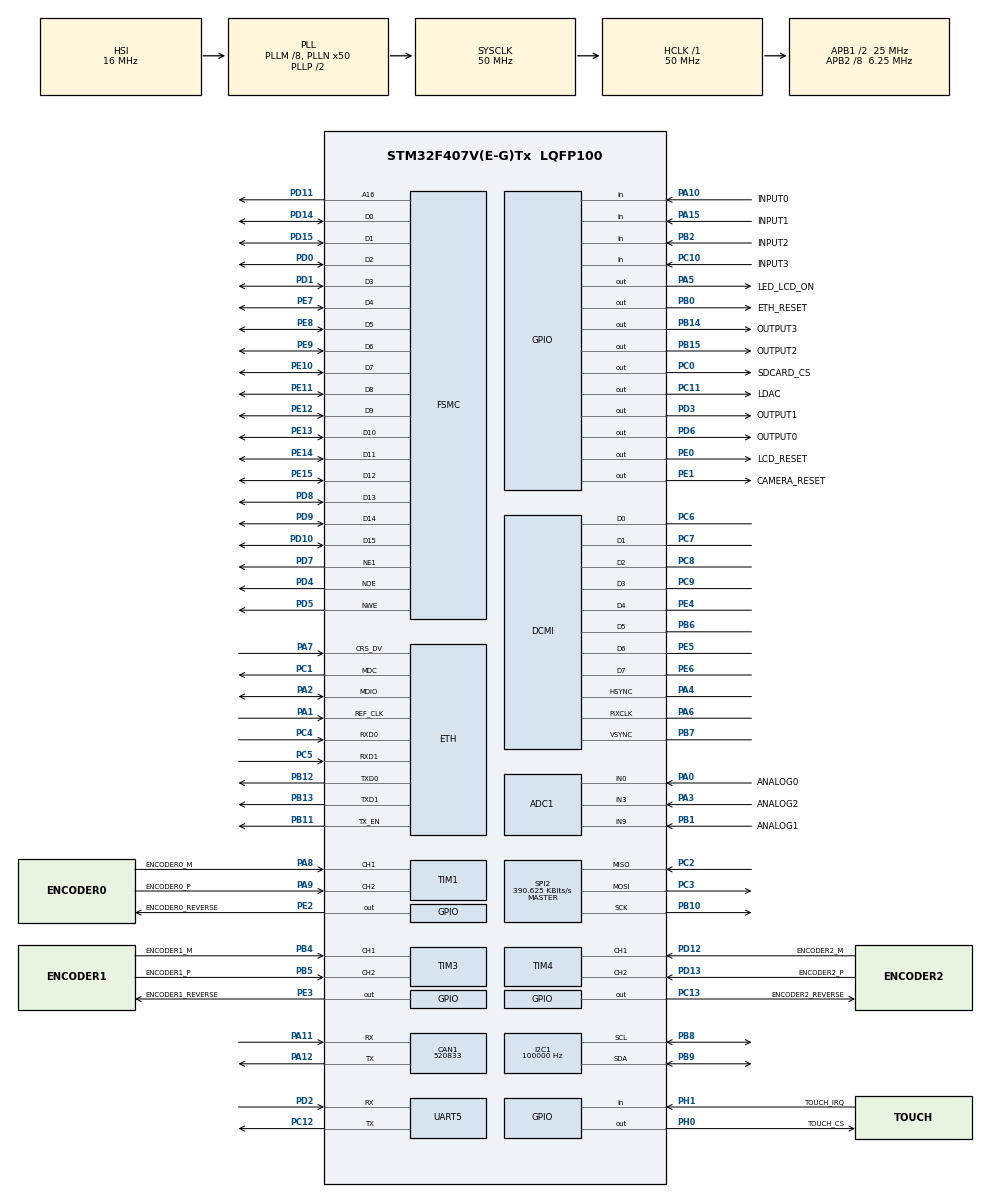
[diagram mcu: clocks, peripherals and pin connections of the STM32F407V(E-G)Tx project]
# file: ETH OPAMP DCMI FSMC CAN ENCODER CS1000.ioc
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ADC1.Channel-0\#ChannelRegularConversion=ADC_CHANNEL_0
ADC1.NbrOfConversionFlag=1
ADC1.Rank-0\#ChannelRegularConversion=1
ADC1.SamplingTime-0\#ChannelRegularConversion=ADC_SAMPLETIME_3CYCLES
ADC1.master=1
CAN1.CalculateBaudRate=520833
CAN1.CalculateTimeBit=1920
CAN1.CalculateTimeQuantum=640.0
ETH.MACAddr=80\:80\:A2\:AE\:13\:41
ETH.MediaInterface=HAL_ETH_RMII_MODE
ETH.PHY_Name_RMII=DP83848_PHY_ADDRESS
ETH.RxBuffLen=1524
ETH.RxMode=ETH_RXPOLLING_MODE
FSMC.AddressSetupTime1=10
FSMC.BusTurnAroundDuration1=0
FSMC.DataSetupTime1=20
I2C1.ClockSpeed=100000
I2C1.DualAddressMode=I2C_DUALADDRESS_DISABLE
LWIP.API_LIB_DEBUG=LWIP_DBG_ON
LWIP.API_MSG_DEBUG=LWIP_DBG_ON
LWIP.AUTOIP_DEBUG=LWIP_DBG_ON
LWIP.BSP.number=1
LWIP.DHCP6_DEBUG=LWIP_DBG_ON
LWIP.DHCP_DEBUG=LWIP_DBG_ON
LWIP.DNS_DEBUG=LWIP_DBG_ON
LWIP.ETHARP_DEBUG=LWIP_DBG_ON
LWIP.GATEWAY_ADDRESS=192.168.001.001
LWIP.HTTPD_DEBUG=LWIP_DBG_ON
LWIP.HTTPD_DEBUG_TIMING=LWIP_DBG_ON
LWIP.ICMP_DEBUG=LWIP_DBG_ON
LWIP.IGMP_DEBUG=LWIP_DBG_ON
LWIP.INET_DEBUG=LWIP_DBG_ON
LWIP.IP6_DEBUG=LWIP_DBG_ON
LWIP.IP_ADDRESS=192.168.001.015
LWIP.IP_DEBUG=LWIP_DBG_ON
LWIP.IP_REASS_DEBUG=LWIP_DBG_ON
LWIP.LWIP_BROADCAST_PING=1
LWIP.LWIP_DHCP=0
LWIP.LWIP_HTTPD=0
LWIP.LWIP_RAM_HEAP_POINTER=0x20019004
LWIP.LWIP_TESTMODE=1
LWIP.MDNS_DEBUG=LWIP_DBG_ON
LWIP.MEMP_DEBUG=LWIP_DBG_ON
LWIP.MEM_DEBUG=LWIP_DBG_ON
LWIP.NETIF_DEBUG=LWIP_DBG_ON
LWIP.NETMASK_ADDRESS=255.255.255.000
LWIP.PBUF_DEBUG=LWIP_DBG_ON
LWIP.PPP_DEBUG=LWIP_DBG_ON
LWIP.RAW_DEBUG=LWIP_DBG_ON
LWIP.SLIP_DEBUG=LWIP_DBG_ON
LWIP.SMTP_DEBUG=LWIP_DBG_ON
LWIP.SNMP_DEBUG=LWIP_DBG_ON
LWIP.SNMP_MIB_DEBUG=LWIP_DBG_ON
LWIP.SNTP_DEBUG=LWIP_DBG_ON
LWIP.SOCKETS_DEBUG=LWIP_DBG_ON
LWIP.SYS_DEBUG=LWIP_DBG_ON
LWIP.TCPIP_DEBUG=LWIP_DBG_ON
LWIP.TCP_CWND_DEBUG=LWIP_DBG_ON
LWIP.TCP_DEBUG=LWIP_DBG_ON
LWIP.TCP_FR_DEBUG=LWIP_DBG_ON
LWIP.TCP_INPUT_DEBUG=LWIP_DBG_ON
LWIP.TCP_OUTPUT_DEBUG=LWIP_DBG_ON
LWIP.TCP_QLEN_DEBUG=LWIP_DBG_ON
LWIP.TCP_RST_DEBUG=LWIP_DBG_ON
LWIP.TCP_RTO_DEBUG=LWIP_DBG_ON
LWIP.TCP_WND_DEBUG=LWIP_DBG_ON
LWIP.TIMERS_DEBUG=LWIP_DBG_ON
LWIP.UDP_DEBUG=LWIP_DBG_ON
LWIP.Version=v2.1.2_Cube
LWIP0.BSP.STBoard=false
LWIP0.BSP.api=BSP_COMPONENT_DRIVER
LWIP0.BSP.component=DP83848
LWIP0.BSP.i2caddr=0
LWIP0.BSP.instance=DP83848
LWIP0.BSP.name=Driver_PHY
LWIP0.BSP.semaphore=S_DP83848
LWIP0.BSP.solution=DP83848
Mcu.Family=STM32F4
Mcu.Name=STM32F407V(E-G)Tx
Mcu.Package=LQFP100
NVIC.PriorityGroup=NVIC_PRIORITYGROUP_4
NVIC.TIM2_IRQn=true\:15\:0\:false\:false\:true\:false\:true\:true
NVIC.TimeBase=TIM2_IRQn
NVIC.TimeBaseIP=TIM2
PA0-WKUP.GPIO_Label=ANALOG0
PA0-WKUP.Signal=ADCx_IN0
PA1.Mode=RMII
PA1.Signal=ETH_REF_CLK
PA10.GPIO_Label=INPUT0
PA10.Signal=GPIO_Input
PA11.Mode=CAN_Activate
PA11.Signal=CAN1_RX
PA12.Mode=CAN_Activate
PA12.Signal=CAN1_TX
PA13.Mode=Trace_Asynchronous_SW
PA13.Signal=SYS_JTMS-SWDIO
PA14.Mode=Trace_Asynchronous_SW
PA14.Signal=SYS_JTCK-SWCLK
PA15.GPIO_Label=INPUT1
PA15.Signal=GPIO_Input
PA2.Mode=RMII
PA2.Signal=ETH_MDIO
PA3.GPIO_Label=ANALOG2
PA3.Signal=ADCx_IN3
PA4.Mode=Slave_8_bits_External_Synchro
PA4.Signal=DCMI_HSYNC
PA5.GPIO_Label=LED_LCD_ON
PA5.Signal=GPIO_Output
PA6.Mode=Slave_8_bits_External_Synchro
PA6.Signal=DCMI_PIXCLK
PA7.Mode=RMII
PA7.Signal=ETH_CRS_DV
PA8.GPIO_Label=ENCODER0_M
PA8.Signal=S_TIM1_CH1
PA9.GPIO_Label=ENCODER0_P
PA9.Signal=S_TIM1_CH2
PB0.GPIO_Label=ETH_RESET
PB0.Signal=GPIO_Output
PB1.GPIO_Label=ANALOG1
PB1.Signal=ADCx_IN9
PB10.Mode=Full_Duplex_Master
PB10.Signal=SPI2_SCK
PB11.Mode=RMII
PB11.Signal=ETH_TX_EN
PB12.GPIO_PuPd=GPIO_NOPULL
PB12.Mode=RMII
PB12.Signal=ETH_TXD0
PB13.GPIO_PuPd=GPIO_NOPULL
PB13.Mode=RMII
PB13.Signal=ETH_TXD1
PB14.GPIO_Label=OUTPUT3
PB14.Signal=GPIO_Output
PB15.GPIO_Label=OUTPUT2
PB15.Signal=GPIO_Output
PB2.GPIO_Label=INPUT2
PB2.Signal=GPIO_Input
PB3.Mode=Trace_Asynchronous_SW
PB3.Signal=SYS_JTDO-SWO
PB4.GPIO_Label=ENCODER1_M
PB4.Signal=S_TIM3_CH1
PB5.GPIO_Label=ENCODER1_P
PB5.Signal=S_TIM3_CH2
PB6.Mode=Slave_8_bits_External_Synchro
PB6.Signal=DCMI_D5
PB7.Mode=Slave_8_bits_External_Synchro
PB7.Signal=DCMI_VSYNC
PB8.GPIO_Pu=GPIO_PULLUP
PB8.Mode=I2C
PB8.Signal=I2C1_SCL
PB9.GPIO_Pu=GPIO_PULLUP
PB9.Mode=I2C
PB9.Signal=I2C1_SDA
PC0.GPIO_Label=SDCARD_CS
PC0.Signal=GPIO_Output
PC1.Mode=RMII
PC1.Signal=ETH_MDC
PC10.GPIO_Label=INPUT3
PC10.Signal=GPIO_Input
PC11.GPIO_Label=LDAC
PC11.GPIO_PuPd=GPIO_PULLUP
PC11.Signal=GPIO_Output
PC12.Mode=Asynchronous
PC12.Signal=UART5_TX
PC13-ANTI_TAMP.GPIO_Label=ENCODER2_REVERSE
PC13-ANTI_TAMP.Signal=GPIO_Output
PC14-OSC32_IN.Mode=LSE-External-Oscillator
PC14-OSC32_IN.Signal=RCC_OSC32_IN
PC15-OSC32_OUT.Mode=LSE-External-Oscillator
PC15-OSC32_OUT.Signal=RCC_OSC32_OUT
PC2.Mode=Full_Duplex_Master
PC2.Signal=SPI2_MISO
PC3.Mode=Full_Duplex_Master
PC3.Signal=SPI2_MOSI
PC4.GPIO_PuPd=GPIO_PULLDOWN
PC4.Mode=RMII
PC4.Signal=ETH_RXD0
PC5.GPIO_PuPd=GPIO_PULLDOWN
PC5.Mode=RMII
PC5.Signal=ETH_RXD1
PC6.Mode=Slave_8_bits_External_Synchro
PC6.Signal=DCMI_D0
PC7.Mode=Slave_8_bits_External_Synchro
PC7.Signal=DCMI_D1
PC8.Mode=Slave_8_bits_External_Synchro
PC8.Signal=DCMI_D2
PC9.Mode=Slave_8_bits_External_Synchro
PC9.Signal=DCMI_D3
PD0.Mode=16b-d1
PD0.Signal=FSMC_D2
PD1.Mode=16b-d1
PD1.Signal=FSMC_D3
PD10.Mode=16b-d1
PD10.Signal=FSMC_D15
PD11.Mode=A16_1
PD11.Signal=FSMC_A16
PD12.GPIO_Label=ENCODER2_M
PD12.Signal=S_TIM4_CH1
PD13.GPIO_Label=ENCODER2_P
PD13.Signal=S_TIM4_CH2
PD14.Mode=16b-d1
PD14.Signal=FSMC_D0
PD15.Mode=16b-d1
PD15.Signal=FSMC_D1
PD2.Mode=Asynchronous
PD2.Signal=UART5_RX
PD3.GPIO_Label=OUTPUT1
PD3.Signal=GPIO_Output
PD4.Mode=Lcd1
PD4.Signal=FSMC_NOE
PD5.Mode=Lcd1
PD5.Signal=FSMC_NWE
PD6.GPIO_Label=OUTPUT0
PD6.Signal=GPIO_Output
PD7.Mode=NorPsramChipSelect1_1
PD7.Signal=FSMC_NE1
PD8.Mode=16b-d1
PD8.Signal=FSMC_D13
PD9.Mode=16b-d1
PD9.Signal=FSMC_D14
PE0.GPIO_Label=LCD_RESET
PE0.Signal=GPIO_Output
PE1.GPIO_Label=CAMERA_RESET
PE1.Signal=GPIO_Output
PE10.Mode=16b-d1
PE10.Signal=FSMC_D7
PE11.Mode=16b-d1
PE11.Signal=FSMC_D8
PE12.Mode=16b-d1
PE12.Signal=FSMC_D9
PE13.Mode=16b-d1
PE13.Signal=FSMC_D10
PE14.Mode=16b-d1
PE14.Signal=FSMC_D11
PE15.Mode=16b-d1
PE15.Signal=FSMC_D12
PE2.GPIO_Label=ENCODER0_REVERSE
PE2.Signal=GPIO_Output
PE3.GPIO_Label=ENCODER1_REVERSE
PE3.Signal=GPIO_Output
PE4.Mode=Slave_8_bits_External_Synchro
PE4.Signal=DCMI_D4
PE5.Mode=Slave_8_bits_External_Synchro
PE5.Signal=DCMI_D6
PE6.Mode=Slave_8_bits_External_Synchro
PE6.Signal=DCMI_D7
PE7.Mode=16b-d1
PE7.Signal=FSMC_D4
PE8.Mode=16b-d1
PE8.Signal=FSMC_D5
PE9.Mode=16b-d1
PE9.Signal=FSMC_D6
PH0-OSC_IN.GPIO_Label=TOUCH_CS
PH0-OSC_IN.Signal=GPIO_Output
PH1-OSC_OUT.GPIO_Label=TOUCH_IRQ
PH1-OSC_OUT.Signal=GPIO_Input
ProjectManager.HeapSize=0x200
ProjectManager.StackSize=0x400
ProjectManager.TargetToolchain=STM32CubeIDE
RCC.48MHZClocksFreq_Value=25000000
RCC.AHBFreq_Value=50000000
RCC.APB1CLKDivider=RCC_HCLK_DIV2
RCC.APB1Freq_Value=25000000
RCC.APB1TimFreq_Value=50000000
RCC.APB2CLKDivider=RCC_HCLK_DIV8
RCC.APB2Freq_Value=6250000
RCC.APB2TimFreq_Value=12500000
RCC.CortexFreq_Value=50000000
RCC.HCLKFreq_Value=50000000
RCC.HSE_VALUE=4000000
RCC.HSI_VALUE=16000000
RCC.LSE_Timout=60000
RCC.PLLM=8
RCC.PLLN=50
RCC.RCC_RTC_Clock_Source=RCC_RTCCLKSOURCE_LSI
RCC.RCC_RTC_Clock_SourceVirtual=RCC_RTCCLKSOURCE_LSE
RCC.SYSCLKFreq_VALUE=50000000
RCC.SYSCLKSource=RCC_SYSCLKSOURCE_PLLCLK
RCC.VCOOutputFreq_Value=100000000
SH.ADCx_IN0.0=ADC1_IN0,IN0
SH.ADCx_IN3.0=ADC1_IN3,IN3
SH.ADCx_IN9.0=ADC1_IN9,IN9
SH.S_TIM1_CH1.0=TIM1_CH1,Encoder_Interface
SH.S_TIM1_CH2.0=TIM1_CH2,Encoder_Interface
SH.S_TIM3_CH1.0=TIM3_CH1,Encoder_Interface
SH.S_TIM3_CH2.0=TIM3_CH2,Encoder_Interface
SH.S_TIM4_CH1.0=TIM4_CH1,Encoder_Interface
SH.S_TIM4_CH2.0=TIM4_CH2,Encoder_Interface
SPI2.BaudRatePrescaler=SPI_BAUDRATEPRESCALER_64
SPI2.CalculateBaudRate=390.625 KBits/s
SPI2.Direction=SPI_DIRECTION_2LINES
SPI2.Mode=SPI_MODE_MASTER
SPI2.VirtualType=VM_MASTER
UART5.VirtualMode=Asynchronous
VP_LWIP_VS_Enabled.Mode=Enabled
VP_RTC_VS_RTC_Activate.Mode=RTC_Enabled
VP_SYS_VS_tim2.Mode=TIM2
board=custom

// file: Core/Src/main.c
/* USER CODE BEGIN Header */
/**
  ******************************************************************************
  * @file           : main.c
  * @brief          : Main program body
  ******************************************************************************
  * @attention
  *
  * <h2><center>&copy; Copyright (c) 2021 STMicroelectronics.
  * All rights reserved.</center></h2>
  *
  * This software component is licensed by ST under BSD 3-Clause license,
  * the "License"; You may not use this file except in compliance with the
  * License. You may obtain a copy of the License at:
  *                        opensource.org/licenses/BSD-3-Clause
  *
  ******************************************************************************
  */
/* USER CODE END Header */
#include "main.h"
#include "lwip.h"

/* USER CODE BEGIN Includes */
#include "STM32_ILI9341_FSMC_16_Bit/ili9341.h"
#include "MCP4728/mcp4728.h"
/* USER CODE END Includes */

/* USER CODE BEGIN PD */
#define min(a,b) (((a)<(b))?(a):(b))
/* USER CODE END PD */

 ADC_HandleTypeDef hadc1;

CAN_HandleTypeDef hcan1;

DCMI_HandleTypeDef hdcmi;

I2C_HandleTypeDef hi2c1;

RTC_HandleTypeDef hrtc;

SPI_HandleTypeDef hspi2;

TIM_HandleTypeDef htim1;
TIM_HandleTypeDef htim3;
TIM_HandleTypeDef htim4;

UART_HandleTypeDef huart5;

SRAM_HandleTypeDef hsram1;

void SystemClock_Config(void);
static void MX_GPIO_Init(void);
static void MX_FSMC_Init(void);
static void MX_DCMI_Init(void);
static void MX_SPI2_Init(void);
static void MX_TIM1_Init(void);
static void MX_TIM3_Init(void);
static void MX_ADC1_Init(void);
static void MX_CAN1_Init(void);
static void MX_RTC_Init(void);
static void MX_TIM4_Init(void);
static void MX_UART5_Init(void);
static void MX_I2C1_Init(void);
/* USER CODE BEGIN PFP */
void demoLCD(int i);
unsigned long testFillScreen();
unsigned long testText();
unsigned long testLines(uint16_t color);
unsigned long testFastLines(uint16_t color1, uint16_t color2);
unsigned long testRects(uint16_t color);
unsigned long testFilledRects(uint16_t color1, uint16_t color2);
unsigned long testFilledCircles(uint8_t radius, uint16_t color);
unsigned long testCircles(uint8_t radius, uint16_t color);
unsigned long testTriangles();
unsigned long testFilledTriangles();
unsigned long testRoundRects();
unsigned long testFilledRoundRects();
unsigned long testDrawImage();
/* USER CODE END PFP */

int main(void)
{

  /* MCU Configuration--------------------------------------------------------*/

  /* Reset of all peripherals, Initializes the Flash interface and the Systick. */
  HAL_Init();

  /* Configure the system clock */
  SystemClock_Config();

  /* Initialize all configured peripherals */
  MX_GPIO_Init();
  MX_FSMC_Init();
  MX_DCMI_Init();
  MX_SPI2_Init();
  MX_TIM1_Init();
  MX_TIM3_Init();
  MX_ADC1_Init();
  MX_CAN1_Init();
  MX_RTC_Init();
  MX_TIM4_Init();
  MX_UART5_Init();
  MX_LWIP_Init();
  MX_I2C1_Init();
  /* USER CODE BEGIN 2 */

  /* Start up LCD */
  HAL_GPIO_WritePin(LCD_RESET_GPIO_Port, LCD_RESET_Pin, GPIO_PIN_SET);
  LCD_BL_ON();
  lcdInit(&hspi2);
  //touchCalibrate();
  //lcdFillRGB(COLOR_BLACK);

  /* Write to MCP4728 */
  mcp4728_init(&hi2c1, 0x4); // Manufacturer I2C settings: A4 (A2 = 1, A1 = 0, A0 = 0)

  /* Set values */
  mcp4728_set_channel_value(MCP4728_CHANNEL_A, 4095);
  mcp4728_set_channel_value(MCP4728_CHANNEL_B, 3000);
  mcp4728_set_channel_value(MCP4728_CHANNEL_C, 2000);
  mcp4728_set_channel_value(MCP4728_CHANNEL_D, 1000);

  /* Set gain */
  mcp4728_set_channel_gain(MCP4728_CHANNEL_A, MCP4728_GAIN_1);
  mcp4728_set_channel_gain(MCP4728_CHANNEL_B, MCP4728_GAIN_1);
  mcp4728_set_channel_gain(MCP4728_CHANNEL_C, MCP4728_GAIN_1);
  mcp4728_set_channel_gain(MCP4728_CHANNEL_D, MCP4728_GAIN_1);

  /* Set power down */
  mcp4728_set_channel_power_down(MCP4728_CHANNEL_A, MCP4728_POWER_DOWN_NORMAL);
  mcp4728_set_channel_power_down(MCP4728_CHANNEL_B, MCP4728_POWER_DOWN_NORMAL);
  mcp4728_set_channel_power_down(MCP4728_CHANNEL_C, MCP4728_POWER_DOWN_NORMAL);
  mcp4728_set_channel_power_down(MCP4728_CHANNEL_D, MCP4728_POWER_DOWN_NORMAL);

  /* Set voltage reference */
  mcp4728_set_channel_vref(MCP4728_CHANNEL_A, MCP4728_VREF_VDD);
  mcp4728_set_channel_vref(MCP4728_CHANNEL_B, MCP4728_VREF_VDD);
  mcp4728_set_channel_vref(MCP4728_CHANNEL_C, MCP4728_VREF_VDD);
  mcp4728_set_channel_vref(MCP4728_CHANNEL_D, MCP4728_VREF_VDD);

  /* Multi write without EEPROM */
  mcp4728_multi_write_command();

  /* USER CODE END 2 */

  /* Infinite loop */
  while (1)
  {

    /* USER CODE BEGIN 3 */
	  //touchPrintCoordinates();
	  //HAL_Delay(500);

  }
  /* USER CODE END 3 */
}

void SystemClock_Config(void)
{
  RCC_OscInitTypeDef RCC_OscInitStruct = {0};
  RCC_ClkInitTypeDef RCC_ClkInitStruct = {0};

  /** Configure the main internal regulator output voltage
  */
  __HAL_RCC_PWR_CLK_ENABLE();
  __HAL_PWR_VOLTAGESCALING_CONFIG(PWR_REGULATOR_VOLTAGE_SCALE1);

  /** Initializes the RCC Oscillators according to the specified parameters
  * in the RCC_OscInitTypeDef structure.
  */
  RCC_OscInitStruct.OscillatorType = RCC_OSCILLATORTYPE_HSI|RCC_OSCILLATORTYPE_LSI;
  RCC_OscInitStruct.HSIState = RCC_HSI_ON;
  RCC_OscInitStruct.HSICalibrationValue = RCC_HSICALIBRATION_DEFAULT;
  RCC_OscInitStruct.LSIState = RCC_LSI_ON;
  RCC_OscInitStruct.PLL.PLLState = RCC_PLL_ON;
  RCC_OscInitStruct.PLL.PLLSource = RCC_PLLSOURCE_HSI;
  RCC_OscInitStruct.PLL.PLLM = 8;
  RCC_OscInitStruct.PLL.PLLN = 50;
  RCC_OscInitStruct.PLL.PLLP = RCC_PLLP_DIV2;
  RCC_OscInitStruct.PLL.PLLQ = 4;
  if (HAL_RCC_OscConfig(&RCC_OscInitStruct) != HAL_OK)
  {
    Error_Handler();
  }

  /** Initializes the CPU, AHB and APB buses clocks
  */
  RCC_ClkInitStruct.ClockType = RCC_CLOCKTYPE_HCLK|RCC_CLOCKTYPE_SYSCLK
                              |RCC_CLOCKTYPE_PCLK1|RCC_CLOCKTYPE_PCLK2;
  RCC_ClkInitStruct.SYSCLKSource = RCC_SYSCLKSOURCE_PLLCLK;
  RCC_ClkInitStruct.AHBCLKDivider = RCC_SYSCLK_DIV1;
  RCC_ClkInitStruct.APB1CLKDivider = RCC_HCLK_DIV2;
  RCC_ClkInitStruct.APB2CLKDivider = RCC_HCLK_DIV8;

  if (HAL_RCC_ClockConfig(&RCC_ClkInitStruct, FLASH_LATENCY_1) != HAL_OK)
  {
    Error_Handler();
  }
}

static void MX_ADC1_Init(void)
{

  ADC_ChannelConfTypeDef sConfig = {0};

  /** Configure the global features of the ADC (Clock, Resolution, Data Alignment and number of conversion)
  */
  hadc1.Instance = ADC1;
  hadc1.Init.ClockPrescaler = ADC_CLOCK_SYNC_PCLK_DIV2;
  hadc1.Init.Resolution = ADC_RESOLUTION_12B;
  hadc1.Init.ScanConvMode = DISABLE;
  hadc1.Init.ContinuousConvMode = DISABLE;
  hadc1.Init.DiscontinuousConvMode = DISABLE;
  hadc1.Init.ExternalTrigConvEdge = ADC_EXTERNALTRIGCONVEDGE_NONE;
  hadc1.Init.ExternalTrigConv = ADC_SOFTWARE_START;
  hadc1.Init.DataAlign = ADC_DATAALIGN_RIGHT;
  hadc1.Init.NbrOfConversion = 1;
  hadc1.Init.DMAContinuousRequests = DISABLE;
  hadc1.Init.EOCSelection = ADC_EOC_SINGLE_CONV;
  if (HAL_ADC_Init(&hadc1) != HAL_OK)
  {
    Error_Handler();
  }

  /** Configure for the selected ADC regular channel its corresponding rank in the sequencer and its sample time.
  */
  sConfig.Channel = ADC_CHANNEL_0;
  sConfig.Rank = 1;
  sConfig.SamplingTime = ADC_SAMPLETIME_3CYCLES;
  if (HAL_ADC_ConfigChannel(&hadc1, &sConfig) != HAL_OK)
  {
    Error_Handler();
  }

}

static void MX_CAN1_Init(void)
{

  hcan1.Instance = CAN1;
  hcan1.Init.Prescaler = 16;
  hcan1.Init.Mode = CAN_MODE_NORMAL;
  hcan1.Init.SyncJumpWidth = CAN_SJW_1TQ;
  hcan1.Init.TimeSeg1 = CAN_BS1_1TQ;
  hcan1.Init.TimeSeg2 = CAN_BS2_1TQ;
  hcan1.Init.TimeTriggeredMode = DISABLE;
  hcan1.Init.AutoBusOff = DISABLE;
  hcan1.Init.AutoWakeUp = DISABLE;
  hcan1.Init.AutoRetransmission = DISABLE;
  hcan1.Init.ReceiveFifoLocked = DISABLE;
  hcan1.Init.TransmitFifoPriority = DISABLE;
  if (HAL_CAN_Init(&hcan1) != HAL_OK)
  {
    Error_Handler();
  }

}

static void MX_DCMI_Init(void)
{

  hdcmi.Instance = DCMI;
  hdcmi.Init.SynchroMode = DCMI_SYNCHRO_HARDWARE;
  hdcmi.Init.PCKPolarity = DCMI_PCKPOLARITY_FALLING;
  hdcmi.Init.VSPolarity = DCMI_VSPOLARITY_LOW;
  hdcmi.Init.HSPolarity = DCMI_HSPOLARITY_LOW;
  hdcmi.Init.CaptureRate = DCMI_CR_ALL_FRAME;
  hdcmi.Init.ExtendedDataMode = DCMI_EXTEND_DATA_8B;
  hdcmi.Init.JPEGMode = DCMI_JPEG_DISABLE;
  if (HAL_DCMI_Init(&hdcmi) != HAL_OK)
  {
    Error_Handler();
  }

}

static void MX_I2C1_Init(void)
{

  hi2c1.Instance = I2C1;
  hi2c1.Init.ClockSpeed = 100000;
  hi2c1.Init.DutyCycle = I2C_DUTYCYCLE_2;
  hi2c1.Init.OwnAddress1 = 0;
  hi2c1.Init.AddressingMode = I2C_ADDRESSINGMODE_7BIT;
  hi2c1.Init.DualAddressMode = I2C_DUALADDRESS_DISABLE;
  hi2c1.Init.OwnAddress2 = 0;
  hi2c1.Init.GeneralCallMode = I2C_GENERALCALL_DISABLE;
  hi2c1.Init.NoStretchMode = I2C_NOSTRETCH_DISABLE;
  if (HAL_I2C_Init(&hi2c1) != HAL_OK)
  {
    Error_Handler();
  }

}

static void MX_RTC_Init(void)
{

  /** Initialize RTC Only
  */
  hrtc.Instance = RTC;
  hrtc.Init.HourFormat = RTC_HOURFORMAT_24;
  hrtc.Init.AsynchPrediv = 127;
  hrtc.Init.SynchPrediv = 255;
  hrtc.Init.OutPut = RTC_OUTPUT_DISABLE;
  hrtc.Init.OutPutPolarity = RTC_OUTPUT_POLARITY_HIGH;
  hrtc.Init.OutPutType = RTC_OUTPUT_TYPE_OPENDRAIN;
  if (HAL_RTC_Init(&hrtc) != HAL_OK)
  {
    Error_Handler();
  }

}

static void MX_SPI2_Init(void)
{

  /* SPI2 parameter configuration*/
  hspi2.Instance = SPI2;
  hspi2.Init.Mode = SPI_MODE_MASTER;
  hspi2.Init.Direction = SPI_DIRECTION_2LINES;
  hspi2.Init.DataSize = SPI_DATASIZE_8BIT;
  hspi2.Init.CLKPolarity = SPI_POLARITY_LOW;
  hspi2.Init.CLKPhase = SPI_PHASE_1EDGE;
  hspi2.Init.NSS = SPI_NSS_SOFT;
  hspi2.Init.BaudRatePrescaler = SPI_BAUDRATEPRESCALER_64;
  hspi2.Init.FirstBit = SPI_FIRSTBIT_MSB;
  hspi2.Init.TIMode = SPI_TIMODE_DISABLE;
  hspi2.Init.CRCCalculation = SPI_CRCCALCULATION_DISABLE;
  hspi2.Init.CRCPolynomial = 10;
  if (HAL_SPI_Init(&hspi2) != HAL_OK)
  {
    Error_Handler();
  }

}

static void MX_TIM1_Init(void)
{

  TIM_Encoder_InitTypeDef sConfig = {0};
  TIM_MasterConfigTypeDef sMasterConfig = {0};

  htim1.Instance = TIM1;
  htim1.Init.Prescaler = 0;
  htim1.Init.CounterMode = TIM_COUNTERMODE_UP;
  htim1.Init.Period = 65535;
  htim1.Init.ClockDivision = TIM_CLOCKDIVISION_DIV1;
  htim1.Init.RepetitionCounter = 0;
  htim1.Init.AutoReloadPreload = TIM_AUTORELOAD_PRELOAD_DISABLE;
  sConfig.EncoderMode = TIM_ENCODERMODE_TI1;
  sConfig.IC1Polarity = TIM_ICPOLARITY_RISING;
  sConfig.IC1Selection = TIM_ICSELECTION_DIRECTTI;
  sConfig.IC1Prescaler = TIM_ICPSC_DIV1;
  sConfig.IC1Filter = 0;
  sConfig.IC2Polarity = TIM_ICPOLARITY_RISING;
  sConfig.IC2Selection = TIM_ICSELECTION_DIRECTTI;
  sConfig.IC2Prescaler = TIM_ICPSC_DIV1;
  sConfig.IC2Filter = 0;
  if (HAL_TIM_Encoder_Init(&htim1, &sConfig) != HAL_OK)
  {
    Error_Handler();
  }
  sMasterConfig.MasterOutputTrigger = TIM_TRGO_RESET;
  sMasterConfig.MasterSlaveMode = TIM_MASTERSLAVEMODE_DISABLE;
  if (HAL_TIMEx_MasterConfigSynchronization(&htim1, &sMasterConfig) != HAL_OK)
  {
    Error_Handler();
  }

}

static void MX_TIM3_Init(void)
{

  TIM_Encoder_InitTypeDef sConfig = {0};
  TIM_MasterConfigTypeDef sMasterConfig = {0};

  htim3.Instance = TIM3;
  htim3.Init.Prescaler = 0;
  htim3.Init.CounterMode = TIM_COUNTERMODE_UP;
  htim3.Init.Period = 65535;
  htim3.Init.ClockDivision = TIM_CLOCKDIVISION_DIV1;
  htim3.Init.AutoReloadPreload = TIM_AUTORELOAD_PRELOAD_DISABLE;
  sConfig.EncoderMode = TIM_ENCODERMODE_TI1;
  sConfig.IC1Polarity = TIM_ICPOLARITY_RISING;
  sConfig.IC1Selection = TIM_ICSELECTION_DIRECTTI;
  sConfig.IC1Prescaler = TIM_ICPSC_DIV1;
  sConfig.IC1Filter = 0;
  sConfig.IC2Polarity = TIM_ICPOLARITY_RISING;
  sConfig.IC2Selection = TIM_ICSELECTION_DIRECTTI;
  sConfig.IC2Prescaler = TIM_ICPSC_DIV1;
  sConfig.IC2Filter = 0;
  if (HAL_TIM_Encoder_Init(&htim3, &sConfig) != HAL_OK)
  {
    Error_Handler();
  }
  sMasterConfig.MasterOutputTrigger = TIM_TRGO_RESET;
  sMasterConfig.MasterSlaveMode = TIM_MASTERSLAVEMODE_DISABLE;
  if (HAL_TIMEx_MasterConfigSynchronization(&htim3, &sMasterConfig) != HAL_OK)
  {
    Error_Handler();
  }

}

static void MX_TIM4_Init(void)
{

  TIM_Encoder_InitTypeDef sConfig = {0};
  TIM_MasterConfigTypeDef sMasterConfig = {0};

  htim4.Instance = TIM4;
  htim4.Init.Prescaler = 0;
  htim4.Init.CounterMode = TIM_COUNTERMODE_UP;
  htim4.Init.Period = 65535;
  htim4.Init.ClockDivision = TIM_CLOCKDIVISION_DIV1;
  htim4.Init.AutoReloadPreload = TIM_AUTORELOAD_PRELOAD_DISABLE;
  sConfig.EncoderMode = TIM_ENCODERMODE_TI1;
  sConfig.IC1Polarity = TIM_ICPOLARITY_RISING;
  sConfig.IC1Selection = TIM_ICSELECTION_DIRECTTI;
  sConfig.IC1Prescaler = TIM_ICPSC_DIV1;
  sConfig.IC1Filter = 0;
  sConfig.IC2Polarity = TIM_ICPOLARITY_RISING;
  sConfig.IC2Selection = TIM_ICSELECTION_DIRECTTI;
  sConfig.IC2Prescaler = TIM_ICPSC_DIV1;
  sConfig.IC2Filter = 0;
  if (HAL_TIM_Encoder_Init(&htim4, &sConfig) != HAL_OK)
  {
    Error_Handler();
  }
  sMasterConfig.MasterOutputTrigger = TIM_TRGO_RESET;
  sMasterConfig.MasterSlaveMode = TIM_MASTERSLAVEMODE_DISABLE;
  if (HAL_TIMEx_MasterConfigSynchronization(&htim4, &sMasterConfig) != HAL_OK)
  {
    Error_Handler();
  }

}

static void MX_UART5_Init(void)
{

  huart5.Instance = UART5;
  huart5.Init.BaudRate = 115200;
  huart5.Init.WordLength = UART_WORDLENGTH_8B;
  huart5.Init.StopBits = UART_STOPBITS_1;
  huart5.Init.Parity = UART_PARITY_NONE;
  huart5.Init.Mode = UART_MODE_TX_RX;
  huart5.Init.HwFlowCtl = UART_HWCONTROL_NONE;
  huart5.Init.OverSampling = UART_OVERSAMPLING_16;
  if (HAL_UART_Init(&huart5) != HAL_OK)
  {
    Error_Handler();
  }

}

static void MX_GPIO_Init(void)
{
  GPIO_InitTypeDef GPIO_InitStruct = {0};

  /* GPIO Ports Clock Enable */
  __HAL_RCC_GPIOE_CLK_ENABLE();
  __HAL_RCC_GPIOC_CLK_ENABLE();
  __HAL_RCC_GPIOH_CLK_ENABLE();
  __HAL_RCC_GPIOA_CLK_ENABLE();
  __HAL_RCC_GPIOB_CLK_ENABLE();
  __HAL_RCC_GPIOD_CLK_ENABLE();

  /*Configure GPIO pin Output Level */
  HAL_GPIO_WritePin(GPIOE, ENCODER0_REVERSE_Pin|ENCODER1_REVERSE_Pin|LCD_RESET_Pin|CAMERA_RESET_Pin, GPIO_PIN_RESET);

  /*Configure GPIO pin Output Level */
  HAL_GPIO_WritePin(GPIOC, ENCODER2_REVERSE_Pin|SDCARD_CS_Pin|LDAC_Pin, GPIO_PIN_RESET);

  /*Configure GPIO pin Output Level */
  HAL_GPIO_WritePin(TOUCH_CS_GPIO_Port, TOUCH_CS_Pin, GPIO_PIN_RESET);

  /*Configure GPIO pin Output Level */
  HAL_GPIO_WritePin(LED_LCD_ON_GPIO_Port, LED_LCD_ON_Pin, GPIO_PIN_RESET);

  /*Configure GPIO pin Output Level */
  HAL_GPIO_WritePin(GPIOB, ETH_RESET_Pin|OUTPUT3_Pin|OUTPUT2_Pin, GPIO_PIN_RESET);

  /*Configure GPIO pin Output Level */
  HAL_GPIO_WritePin(GPIOD, OUTPUT1_Pin|OUTPUT0_Pin, GPIO_PIN_RESET);

  /*Configure GPIO pins : ENCODER0_REVERSE_Pin ENCODER1_REVERSE_Pin LCD_RESET_Pin CAMERA_RESET_Pin */
  GPIO_InitStruct.Pin = ENCODER0_REVERSE_Pin|ENCODER1_REVERSE_Pin|LCD_RESET_Pin|CAMERA_RESET_Pin;
  GPIO_InitStruct.Mode = GPIO_MODE_OUTPUT_PP;
  GPIO_InitStruct.Pull = GPIO_NOPULL;
  GPIO_InitStruct.Speed = GPIO_SPEED_FREQ_LOW;
  HAL_GPIO_Init(GPIOE, &GPIO_InitStruct);

  /*Configure GPIO pins : ENCODER2_REVERSE_Pin SDCARD_CS_Pin */
  GPIO_InitStruct.Pin = ENCODER2_REVERSE_Pin|SDCARD_CS_Pin;
  GPIO_InitStruct.Mode = GPIO_MODE_OUTPUT_PP;
  GPIO_InitStruct.Pull = GPIO_NOPULL;
  GPIO_InitStruct.Speed = GPIO_SPEED_FREQ_LOW;
  HAL_GPIO_Init(GPIOC, &GPIO_InitStruct);

  /*Configure GPIO pin : TOUCH_CS_Pin */
  GPIO_InitStruct.Pin = TOUCH_CS_Pin;
  GPIO_InitStruct.Mode = GPIO_MODE_OUTPUT_PP;
  GPIO_InitStruct.Pull = GPIO_NOPULL;
  GPIO_InitStruct.Speed = GPIO_SPEED_FREQ_LOW;
  HAL_GPIO_Init(TOUCH_CS_GPIO_Port, &GPIO_InitStruct);

  /*Configure GPIO pin : TOUCH_IRQ_Pin */
  GPIO_InitStruct.Pin = TOUCH_IRQ_Pin;
  GPIO_InitStruct.Mode = GPIO_MODE_INPUT;
  GPIO_InitStruct.Pull = GPIO_NOPULL;
  HAL_GPIO_Init(TOUCH_IRQ_GPIO_Port, &GPIO_InitStruct);

  /*Configure GPIO pin : LED_LCD_ON_Pin */
  GPIO_InitStruct.Pin = LED_LCD_ON_Pin;
  GPIO_InitStruct.Mode = GPIO_MODE_OUTPUT_PP;
  GPIO_InitStruct.Pull = GPIO_NOPULL;
  GPIO_InitStruct.Speed = GPIO_SPEED_FREQ_LOW;
  HAL_GPIO_Init(LED_LCD_ON_GPIO_Port, &GPIO_InitStruct);

  /*Configure GPIO pins : ETH_RESET_Pin OUTPUT3_Pin OUTPUT2_Pin */
  GPIO_InitStruct.Pin = ETH_RESET_Pin|OUTPUT3_Pin|OUTPUT2_Pin;
  GPIO_InitStruct.Mode = GPIO_MODE_OUTPUT_PP;
  GPIO_InitStruct.Pull = GPIO_NOPULL;
  GPIO_InitStruct.Speed = GPIO_SPEED_FREQ_LOW;
  HAL_GPIO_Init(GPIOB, &GPIO_InitStruct);

  /*Configure GPIO pin : INPUT2_Pin */
  GPIO_InitStruct.Pin = INPUT2_Pin;
  GPIO_InitStruct.Mode = GPIO_MODE_INPUT;
  GPIO_InitStruct.Pull = GPIO_NOPULL;
  HAL_GPIO_Init(INPUT2_GPIO_Port, &GPIO_InitStruct);

  /*Configure GPIO pins : INPUT0_Pin INPUT1_Pin */
  GPIO_InitStruct.Pin = INPUT0_Pin|INPUT1_Pin;
  GPIO_InitStruct.Mode = GPIO_MODE_INPUT;
  GPIO_InitStruct.Pull = GPIO_NOPULL;
  HAL_GPIO_Init(GPIOA, &GPIO_InitStruct);

  /*Configure GPIO pin : INPUT3_Pin */
  GPIO_InitStruct.Pin = INPUT3_Pin;
  GPIO_InitStruct.Mode = GPIO_MODE_INPUT;
  GPIO_InitStruct.Pull = GPIO_NOPULL;
  HAL_GPIO_Init(INPUT3_GPIO_Port, &GPIO_InitStruct);

  /*Configure GPIO pin : LDAC_Pin */
  GPIO_InitStruct.Pin = LDAC_Pin;
  GPIO_InitStruct.Mode = GPIO_MODE_OUTPUT_PP;
  GPIO_InitStruct.Pull = GPIO_PULLUP;
  GPIO_InitStruct.Speed = GPIO_SPEED_FREQ_LOW;
  HAL_GPIO_Init(LDAC_GPIO_Port, &GPIO_InitStruct);

  /*Configure GPIO pins : OUTPUT1_Pin OUTPUT0_Pin */
  GPIO_InitStruct.Pin = OUTPUT1_Pin|OUTPUT0_Pin;
  GPIO_InitStruct.Mode = GPIO_MODE_OUTPUT_PP;
  GPIO_InitStruct.Pull = GPIO_NOPULL;
  GPIO_InitStruct.Speed = GPIO_SPEED_FREQ_LOW;
  HAL_GPIO_Init(GPIOD, &GPIO_InitStruct);

}

/* FSMC initialization function */
static void MX_FSMC_Init(void)
{

  FSMC_NORSRAM_TimingTypeDef Timing = {0};

  /** Perform the SRAM1 memory initialization sequence
  */
  hsram1.Instance = FSMC_NORSRAM_DEVICE;
  hsram1.Extended = FSMC_NORSRAM_EXTENDED_DEVICE;
  /* hsram1.Init */
  hsram1.Init.NSBank = FSMC_NORSRAM_BANK1;
  hsram1.Init.DataAddressMux = FSMC_DATA_ADDRESS_MUX_DISABLE;
  hsram1.Init.MemoryType = FSMC_MEMORY_TYPE_SRAM;
  hsram1.Init.MemoryDataWidth = FSMC_NORSRAM_MEM_BUS_WIDTH_16;
  hsram1.Init.BurstAccessMode = FSMC_BURST_ACCESS_MODE_DISABLE;
  hsram1.Init.WaitSignalPolarity = FSMC_WAIT_SIGNAL_POLARITY_LOW;
  hsram1.Init.WrapMode = FSMC_WRAP_MODE_DISABLE;
  hsram1.Init.WaitSignalActive = FSMC_WAIT_TIMING_BEFORE_WS;
  hsram1.Init.WriteOperation = FSMC_WRITE_OPERATION_ENABLE;
  hsram1.Init.WaitSignal = FSMC_WAIT_SIGNAL_DISABLE;
  hsram1.Init.ExtendedMode = FSMC_EXTENDED_MODE_DISABLE;
  hsram1.Init.AsynchronousWait = FSMC_ASYNCHRONOUS_WAIT_DISABLE;
  hsram1.Init.WriteBurst = FSMC_WRITE_BURST_DISABLE;
  hsram1.Init.PageSize = FSMC_PAGE_SIZE_NONE;
  /* Timing */
  Timing.AddressSetupTime = 10;
  Timing.AddressHoldTime = 15;
  Timing.DataSetupTime = 20;
  Timing.BusTurnAroundDuration = 0;
  Timing.CLKDivision = 16;
  Timing.DataLatency = 17;
  Timing.AccessMode = FSMC_ACCESS_MODE_A;
  /* ExtTiming */

  if (HAL_SRAM_Init(&hsram1, &Timing, NULL) != HAL_OK)
  {
    Error_Handler( );
  }

}

/* USER CODE BEGIN 4 */
void demoLCD(int i)
{
	lcdSetOrientation(i % 4);

	uint32_t t = testFillScreen();
	lcdSetTextFont(&Font16);
	lcdSetCursor(0, lcdGetHeight() - lcdGetTextFont()->Height - 1);
	lcdSetTextColor(COLOR_WHITE, COLOR_BLACK);
	lcdPrintf("Time: %4lu ms", t);
	HAL_Delay(2000);

	t = HAL_GetTick();
	lcdTest();
	lcdSetTextFont(&Font16);
	lcdSetCursor(0, lcdGetHeight() - lcdGetTextFont()->Height - 1);
	lcdSetTextColor(COLOR_WHITE, COLOR_BLACK);
	lcdPrintf("Time: %4lu ms", HAL_GetTick() - t);
	HAL_Delay(2000);

	t = testText();
	lcdSetTextFont(&Font16);
	lcdSetCursor(0, lcdGetHeight() - lcdGetTextFont()->Height - 1);
	lcdSetTextColor(COLOR_WHITE, COLOR_BLACK);
	lcdPrintf("Time: %4lu ms", t);
	HAL_Delay(2000);

	lcdSetTextFont(&Font16);
	lcdSetCursor(0, lcdGetHeight() - lcdGetTextFont()->Height - 1);
	lcdSetTextColor(COLOR_WHITE, COLOR_BLACK);
	lcdPrintf("Time: %4lu ms", testLines(COLOR_CYAN));
	HAL_Delay(2000);

	lcdSetTextFont(&Font16);
	lcdSetCursor(0, lcdGetHeight() - lcdGetTextFont()->Height - 1);
	lcdSetTextColor(COLOR_WHITE, COLOR_BLACK);
	lcdPrintf("Time: %4lu ms", testFastLines(COLOR_RED, COLOR_BLUE));
	HAL_Delay(2000);

	lcdSetTextFont(&Font16);
	lcdSetCursor(0, lcdGetHeight() - lcdGetTextFont()->Height - 1);
	lcdSetTextColor(COLOR_WHITE, COLOR_BLACK);
	lcdPrintf("Time: %4lu ms", testRects(COLOR_GREEN));
	HAL_Delay(2000);

	lcdSetTextFont(&Font16);
	lcdSetCursor(0, lcdGetHeight() - lcdGetTextFont()->Height - 1);
	lcdSetTextColor(COLOR_WHITE, COLOR_BLACK);
	lcdPrintf("Time: %4lu ms", testFilledRects(COLOR_YELLOW, COLOR_MAGENTA));
	HAL_Delay(2000);

	lcdSetTextFont(&Font16);
	lcdSetCursor(0, lcdGetHeight() - lcdGetTextFont()->Height - 1);
	lcdSetTextColor(COLOR_WHITE, COLOR_BLACK);
	lcdPrintf("Time: %4lu ms", testFilledCircles(10, COLOR_MAGENTA));
	HAL_Delay(2000);

	lcdSetTextFont(&Font16);
	lcdSetCursor(0, lcdGetHeight() - lcdGetTextFont()->Height - 1);
	lcdSetTextColor(COLOR_WHITE, COLOR_BLACK);
	lcdPrintf("Time: %4lu ms", testCircles(10, COLOR_WHITE));
	HAL_Delay(2000);

	lcdSetTextFont(&Font16);
	lcdSetCursor(0, lcdGetHeight() - lcdGetTextFont()->Height - 1);
	lcdSetTextColor(COLOR_WHITE, COLOR_BLACK);
	lcdPrintf("Time: %4lu ms", testTriangles());
	HAL_Delay(2000);

	lcdSetTextFont(&Font16);
	lcdSetCursor(0, lcdGetHeight() - lcdGetTextFont()->Height - 1);
	lcdSetTextColor(COLOR_WHITE, COLOR_BLACK);
	lcdPrintf("Time: %4lu ms", testFilledTriangles());
	HAL_Delay(2000);

	lcdSetTextFont(&Font16);
	lcdSetCursor(0, lcdGetHeight() - lcdGetTextFont()->Height - 1);
	lcdSetTextColor(COLOR_WHITE, COLOR_BLACK);
	lcdPrintf("Time: %4lu ms", testRoundRects());
	HAL_Delay(2000);

	lcdSetTextFont(&Font16);
	lcdSetCursor(0, lcdGetHeight() - lcdGetTextFont()->Height - 1);
	lcdSetTextColor(COLOR_WHITE, COLOR_BLACK);
	lcdPrintf("Time: %4lu ms", testFilledRoundRects());
	HAL_Delay(2000);

	lcdSetTextFont(&Font16);
	lcdSetCursor(0, lcdGetHeight() - lcdGetTextFont()->Height - 1);
	lcdSetTextColor(COLOR_WHITE, COLOR_BLACK);
	lcdPrintf("Time: %4lu ms", testDrawImage());
	HAL_Delay(2000);
}

unsigned long testFillScreen()
{
	unsigned long start = HAL_GetTick(), t = 0;
	lcdFillRGB(COLOR_BLACK);
	t += HAL_GetTick() - start;
	lcdSetCursor(0, 0);
	lcdSetTextFont(&Font24);
	lcdSetTextColor(COLOR_WHITE, COLOR_BLACK);
	lcdPrintf("BLACK");
	HAL_Delay(1000);
	start = HAL_GetTick();
	lcdFillRGB(COLOR_RED);
	t += HAL_GetTick() - start;
	lcdSetCursor(0, 0);
	lcdSetTextFont(&Font24);
	lcdSetTextColor(COLOR_WHITE, COLOR_BLACK);
	lcdPrintf("RED");
	HAL_Delay(1000);
	start = HAL_GetTick();
	lcdFillRGB(COLOR_GREEN);
	t += HAL_GetTick() - start;
	lcdSetCursor(0, 0);
	lcdSetTextFont(&Font24);
	lcdSetTextColor(COLOR_WHITE, COLOR_BLACK);
	lcdPrintf("GREEN");
	HAL_Delay(1000);
	start = HAL_GetTick();
	lcdFillRGB(COLOR_BLUE);
	t += HAL_GetTick() - start;
	lcdSetCursor(0, 0);
	lcdSetTextFont(&Font24);
	lcdSetTextColor(COLOR_WHITE, COLOR_BLACK);
	lcdPrintf("BLUE");
	HAL_Delay(1000);
	start = HAL_GetTick();
	lcdFillRGB(COLOR_BLACK);
	return t += HAL_GetTick() - start;
}

unsigned long testText()
{
	lcdFillRGB(COLOR_BLACK);
	unsigned long start = HAL_GetTick();
	lcdSetCursor(0, 0);
	lcdSetTextColor(COLOR_WHITE, COLOR_BLACK);
	lcdSetTextFont(&Font8);
	lcdPrintf("Hello World!\r\n");
	lcdSetTextColor(COLOR_YELLOW, COLOR_BLACK);
	lcdSetTextFont(&Font12);
	lcdPrintf("%i\r\n", 1234567890);
	lcdSetTextColor(COLOR_RED, COLOR_BLACK);
	lcdSetTextFont(&Font16);
	lcdPrintf("%#X\r\n", 0xDEADBEEF);
	lcdPrintf("\r\n");
	lcdSetTextColor(COLOR_GREEN, COLOR_BLACK);
	lcdSetTextFont(&Font20);
	lcdPrintf("Groop\r\n");
	lcdSetTextFont(&Font12);
	lcdPrintf("I implore thee,\r\n");
	lcdSetTextFont(&Font12);
	lcdPrintf("my foonting turlingdromes.\r\n");
	lcdPrintf("And hooptiously drangle me\r\n");
	lcdPrintf("with crinkly bindlewurdles,\r\n");
	lcdPrintf("Or I will rend thee\r\n");
	lcdPrintf("in the gobberwarts\r\n");
	lcdPrintf("with my blurglecruncheon,\r\n");
	lcdPrintf("see if I don't!\r\n");
	return HAL_GetTick() - start;
}

unsigned long testLines(uint16_t color)
{
  unsigned long start, t;
  int           x1, y1, x2, y2,
                w = lcdGetWidth(),
                h = lcdGetHeight();

  lcdFillRGB(COLOR_BLACK);

  x1 = y1 = 0;
  y2    = h - 1;
  start = HAL_GetTick();
  for(x2 = 0; x2 < w; x2 += 6) lcdDrawLine(x1, y1, x2, y2, color);
  x2 = w - 1;
  for(y2 = 0; y2 < h; y2 += 6) lcdDrawLine(x1, y1, x2, y2, color);
  t = HAL_GetTick() - start; // fillScreen doesn't count against timing

  HAL_Delay(1000);
  lcdFillRGB(COLOR_BLACK);

  x1 = w - 1;
  y1 = 0;
  y2 = h - 1;

  start = HAL_GetTick();

  for(x2 = 0; x2 < w; x2 += 6) lcdDrawLine(x1, y1, x2, y2, color);
  x2 = 0;
  for(y2 = 0; y2 < h; y2 += 6) lcdDrawLine(x1, y1, x2, y2, color);
  t += HAL_GetTick() - start;

  HAL_Delay(1000);
  lcdFillRGB(COLOR_BLACK);

  x1 = 0;
  y1 = h - 1;
  y2 = 0;
  start = HAL_GetTick();

  for(x2 = 0; x2 < w; x2 += 6) lcdDrawLine(x1, y1, x2, y2, color);
  x2 = w - 1;
  for(y2 = 0; y2 < h; y2 += 6) lcdDrawLine(x1, y1, x2, y2, color);
  t += HAL_GetTick() - start;

  HAL_Delay(1000);
  lcdFillRGB(COLOR_BLACK);

  x1 = w - 1;
  y1 = h - 1;
  y2 = 0;

  start = HAL_GetTick();

  for(x2 = 0; x2 < w; x2 += 6) lcdDrawLine(x1, y1, x2, y2, color);
  x2 = 0;
  for(y2 = 0; y2 < h; y2 += 6) lcdDrawLine(x1, y1, x2, y2, color);

  return t += HAL_GetTick() - start;
}

unsigned long testFastLines(uint16_t color1, uint16_t color2)
{
  unsigned long start;
  int x, y, w = lcdGetWidth(), h = lcdGetHeight();

  lcdFillRGB(COLOR_BLACK);
  start = HAL_GetTick();
  for(y = 0; y < h; y += 5) lcdDrawHLine(0, w, y, color1);
  for(x = 0; x < w; x += 5) lcdDrawVLine(x, 0, h, color2);

  return HAL_GetTick() - start;
}

unsigned long testRects(uint16_t color)
{
  unsigned long start;
  int n, i, i2,
      cx = lcdGetWidth()  / 2,
      cy = lcdGetHeight() / 2;

  lcdFillRGB(COLOR_BLACK);
  n = min(lcdGetWidth(), lcdGetHeight());
  start = HAL_GetTick();
  for(i = 2; i < n; i += 6)
  {
    i2 = i / 2;
    lcdDrawRect(cx - i2, cy - i2, i, i, color);
  }

  return HAL_GetTick() - start;
}

unsigned long testFilledRects(uint16_t color1, uint16_t color2)
{
  unsigned long start, t = 0;
  int n, i, i2,
      cx = lcdGetWidth() / 2 - 1,
      cy = lcdGetHeight() / 2 - 1;

  lcdFillRGB(COLOR_BLACK);
  n = min(lcdGetWidth(), lcdGetHeight());

  for(i = n; i > 0; i -= 6)
  {
    i2 = i / 2;
    start = HAL_GetTick();
    lcdFillRect(cx-i2, cy-i2, i, i, color1);
    t    += HAL_GetTick() - start;
    // Outlines are not included in timing results
    lcdDrawRect(cx-i2, cy-i2, i, i, color1);
  }

  return t;
}

unsigned long testFilledCircles(uint8_t radius, uint16_t color)
{
  unsigned long start;
  int x, y, w = lcdGetWidth(), h = lcdGetHeight(), r2 = radius * 2;

  lcdFillRGB(COLOR_BLACK);
  start = HAL_GetTick();
  for(x = radius; x < w; x += r2)
  {
    for(y = radius; y < h; y += r2)
    {
      lcdFillCircle(x, y, radius, color);
    }
  }

  return HAL_GetTick() - start;
}

unsigned long testCircles(uint8_t radius, uint16_t color)
{
  unsigned long start;
  int x, y, r2 = radius * 2,
      w = lcdGetWidth()  + radius,
      h = lcdGetHeight() + radius;

  // Screen is not cleared for this one -- this is
  // intentional and does not affect the reported time.
  start = HAL_GetTick();
  for(x = 0; x < w; x += r2)
  {
    for(y = 0; y < h; y += r2)
    {
      lcdDrawCircle(x, y, radius, color);
    }
  }

  return HAL_GetTick() - start;
}

unsigned long testTriangles()
{
  unsigned long start;
  int n, i, cx = lcdGetWidth() / 2 - 1,
            cy = lcdGetHeight() / 2 - 1;

  lcdFillRGB(COLOR_BLACK);
  n = min(cx, cy);
  start = HAL_GetTick();
  for(i = 0; i < n; i += 5)
  {
    lcdDrawTriangle(
      cx    , cy - i, // peak
      cx - i, cy + i, // bottom left
      cx + i, cy + i, // bottom right
      lcdColor565(i, i, i));
  }

  return HAL_GetTick() - start;
}

unsigned long testFilledTriangles()
{
  unsigned long start, t = 0;
  int i, cx = lcdGetWidth() / 2 - 1,
         cy = lcdGetHeight() / 2 - 1;

  lcdFillRGB(COLOR_BLACK);
  for(i = min(cx, cy); i > 10; i -= 5)
  {
    start = HAL_GetTick();
    lcdFillTriangle(cx, cy - i, cx - i, cy + i, cx + i, cy + i, lcdColor565(0, i*10, i*10));
    t += HAL_GetTick() - start;
    lcdFillTriangle(cx, cy - i, cx - i, cy + i, cx + i, cy + i, lcdColor565(i*10, i*10, 0));
  }

  return t;
}

unsigned long testRoundRects()
{
  unsigned long start;
  int w, i, i2,
      cx = lcdGetWidth() / 2 - 1,
      cy = lcdGetHeight() / 2 - 1;

  lcdFillRGB(COLOR_BLACK);
  w = lcdGetWidth(), lcdGetHeight();
  start = HAL_GetTick();
  for(i = 0; i < w; i += 6)
  {
    i2 = i / 2;
    lcdDrawRoundRect(cx-i2, cy-i2, i, i, i/8, lcdColor565(i, 0, 0));
  }

  return HAL_GetTick() - start;
}

unsigned long testFilledRoundRects()
{
  unsigned long start;
  int i, i2,
      cx = lcdGetWidth()  / 2 - 1,
      cy = lcdGetHeight() / 2 - 1;

  lcdFillRGB(COLOR_BLACK);
  start = HAL_GetTick();
  for(i = min(lcdGetWidth(), lcdGetHeight()); i > 20; i -=6 )
  {
    i2 = i / 2;
    lcdFillRoundRect(cx - i2, cy - i2, i, i, i / 8, lcdColor565(0, i, 0));
  }

  return HAL_GetTick() - start;
}

unsigned long testDrawImage()
{
	unsigned long start;

	lcdFillRGB(COLOR_BLACK);
	start = HAL_GetTick();
	if (lcdGetOrientation() == LCD_ORIENTATION_LANDSCAPE || lcdGetOrientation() == LCD_ORIENTATION_LANDSCAPE_MIRROR)
	{
		lcdDrawImage((lcdGetWidth() - bmSTLogo.xSize) / 2, 0, &bmSTLogo);
	}
	else
	{
		lcdDrawImage(0, (lcdGetHeight() - bmSTLogo.ySize) / 2, &bmSTLogo);
	}
	return HAL_GetTick() - start;
}
/* USER CODE END 4 */

void HAL_TIM_PeriodElapsedCallback(TIM_HandleTypeDef *htim)
{
  if (htim->Instance == TIM2) {
    HAL_IncTick();
  }
}

void Error_Handler(void)
{
  __disable_irq();
  while (1)
  {
  }
}
